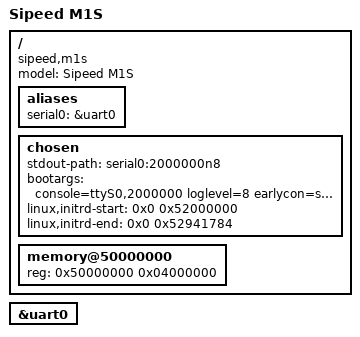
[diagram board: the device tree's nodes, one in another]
// SPDX-License-Identifier: (GPL-2.0+ or MIT)
/*
 * Copyright (C) 2022 Jisheng Zhang <jszhang@kernel.org>
 */

/dts-v1/;

#include "bl808.dtsi"

/ {
	model = "Sipeed M1S";
	compatible = "sipeed,m1s", "bouffalolab,bl808";

	aliases {
		serial0 = &uart0;
	};

	chosen {
		stdout-path = "serial0:2000000n8";
		bootargs = "console=ttyS0,2000000 loglevel=8 earlycon=sbi root=/dev/mtdblock0 ro rootfstype=squashfs";
		linux,initrd-start = <0x0 0x52000000>;
		linux,initrd-end = <0x0 0x52941784>;
	};

	memory@50000000 {
		device_type = "memory";
		reg = <0x50000000 0x04000000>;
	};
};

&uart0 {
	status = "okay";
};
